VERSION ""

NS_ :

BS_:

BU_: DEMO

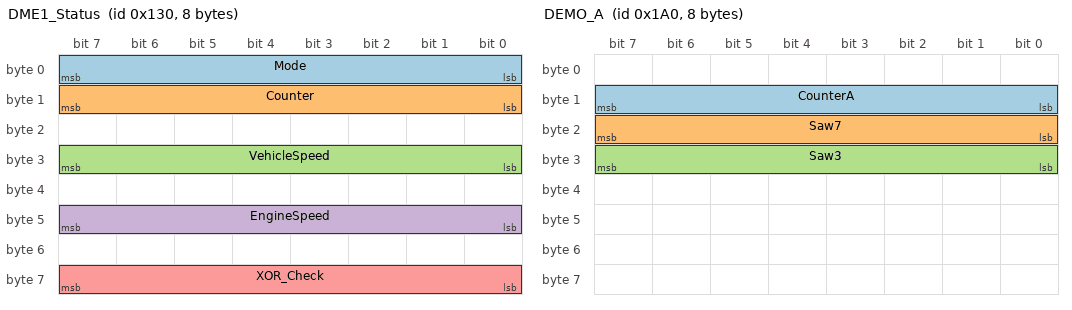
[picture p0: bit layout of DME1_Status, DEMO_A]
BO_ 304 DME1_Status: 8 DEMO
 SG_ Mode : 0|8@1+ (1,0) [0|255] "" DEMO
 SG_ Counter : 8|8@1+ (1,0) [0|255] "" DEMO
 SG_ VehicleSpeed : 24|8@1+ (1,0) [0|255] "km/h" DEMO
 SG_ EngineSpeed : 40|8@1+ (12,0) [900|3000] "rpm" DEMO
 SG_ XOR_Check : 56|8@1+ (1,0) [0|255] "" DEMO

BO_ 416 DEMO_A: 8 DEMO
 SG_ CounterA : 8|8@1+ (1,0) [0|255] "" DEMO
 SG_ Saw7 : 16|8@1+ (1,0) [0|255] "" DEMO
 SG_ Saw3 : 24|8@1+ (1,0) [0|255] "" DEMO

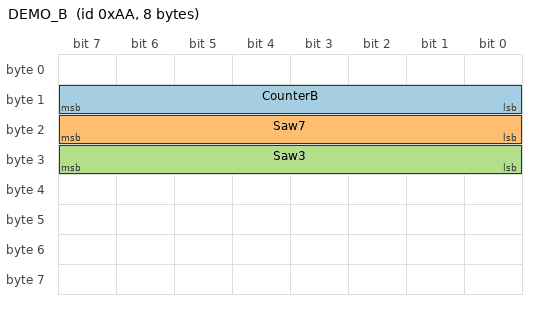
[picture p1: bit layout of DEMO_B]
BO_ 170 DEMO_B: 8 DEMO
 SG_ CounterB : 8|8@1+ (1,0) [0|255] "" DEMO
 SG_ Saw7 : 16|8@1+ (1,0) [0|255] "" DEMO
 SG_ Saw3 : 24|8@1+ (1,0) [0|255] "" DEMO

CM_ BO_ 304 "Wiadomosc DEMO GUI (generator wbudowany w CAN Studio) - nie jest to ramka z samochodu.";
CM_ SG_ 304 EngineSpeed "Obroty demo (skala 12).";
CM_ SG_ 304 VehicleSpeed "Predkosc demo.";
